# CC2753 register map
File version: 1.0
CPU: CM0+ r0p4, little endian, no MPU, no FPU, VTOR, 3 interrupt priority bits
Registers are 32-bit, read-write, reset 0x0 unless marked. A register's access mark holds for its fields unless they carry their own. Offsets are from the block's base; [hi:lo] are bit positions; {n}, {i} and the like mark numbered series; 'fields as' and 'values as' point back to an identical list.

## SYS0 — This is top module of SYS0
Base 0x40004000
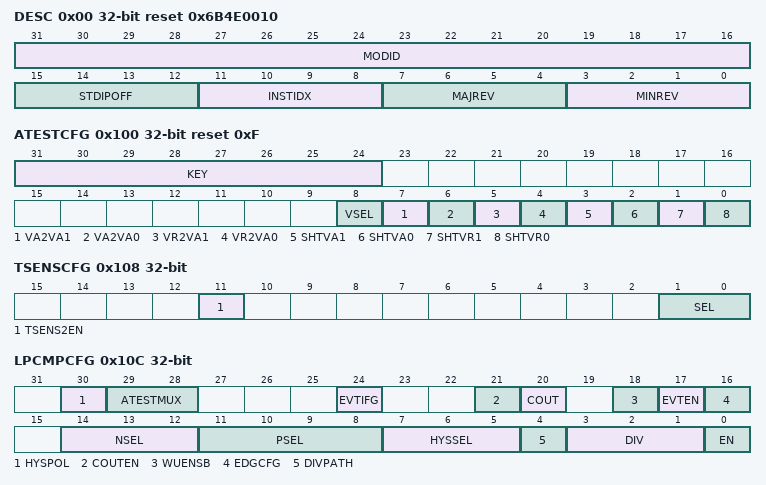
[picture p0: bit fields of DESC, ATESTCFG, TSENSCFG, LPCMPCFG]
0x00 DESC ro reset 0x6B4E0010 — Description Register This register provides IP module ID, revision information, instance index and standard MMR registers offset.
  [31:16] MODID — Module Identifier is used to uniquely identify this IP
  [15:12] STDIPOFF — Standard IP MMR block offset. Standard IP MMRs are the set from aggregated IRQ registers till DTB. 0: Standard IP MMRs do not exist 0x1-0xF: Standard IP MMRs begin at offset of (64*STDIPOFF from the base IP address)
  [11:8] INSTIDX — IP Instance ID number. If multiple instances of IP exist in the device, this field can identify the instance number (0-15).
  [7:4] MAJREV — Major revision of IP (0-15).
  [3:0] MINREV — Minor revision of IP (0-15).
0x0C MUNLOCK wo — Mutable section Unlock This register unlocks registers in mutable section
  [31:0] KEY — Write the unlock key 0xC5AF6927 to temporarily unlock registers in mutable section. The lock is set automatically if no write accesses, to the mutable section, are detected for consecutive 32 CLKULL (24MHz) clock cycles. Writing any value other than that, the unlock key will immediately lock the mutable register space for write access.
    0xC5AF6927=UNLOCK (Unlock registers in the mutable section); 0=LOCK (Lock registers in the mutable section)
0x100 ATESTCFG reset 0xF — ATEST Configuration This register is used to configure analog switches in ATEST module.
  [31:24] KEY wo — Key must be written with value 0x5A for successful write to ATESTCFG and to unlock register state. Write with any value other than 0x5A to KEY will be ignored and register content is not updated. It is recommended to write this register with incorrect KEY to lock back register state after necessary ATESTCFG updates are done. Read value of KEY is 0x0.
  [8] VSEL — Selects supply for ATEST switches.
    1=VDDS (Selects VDDS); 0=VDDBST (Selects VDDBOOST)
  [7] VA2VA1 — Enables isolation switch between VA_ATEST_A1 and VA_PAD_A1.
    1=CLOSE (Switch is closed); 0=OPEN (Switch is open)
  [6] VA2VA0 — Enables isolation switch between VA_ATEST_A0 and VA_PAD_A0.
    1=CLOSE (Switch is closed); 0=OPEN (Switch is open)
  [5] VR2VA1 — Enables isolation switch between VR_ATEST_A1 and VA_ATEST_A1.
    1=CLOSE (Switch is closed); 0=OPEN (Switch is open)
  [4] VR2VA0 — Enables isolation switch between VR_ATEST_A0 and VA_ATEST_A0.
    1=CLOSE (Switch is closed); 0=OPEN (Switch is open)
  [3] SHTVA1 — Shorts VA_ATEST_A1 to ground.
    1=CLOSE (Switch is closed); 0=OPEN (Switch is open)
  [2] SHTVA0 — Shorts VA_ATEST_A0 to ground.
    1=CLOSE (Switch is closed); 0=OPEN (Switch is open)
  [1] SHTVR1 — Shorts VR_ATEST_A1 to ground.
    1=CLOSE (Switch is closed); 0=OPEN (Switch is open)
  [0] SHTVR0 — Shorts VR_ATEST_A0 to ground.
    1=CLOSE (Switch is closed); 0=OPEN (Switch is open)
0x108 TSENSCFG — TSENSE Configuration This register is used to configure temperature sensor module.
  [11] TSENS2EN — This is the enable bit for the second temperature sensor in AUX.
    1=EN (Second temperature sensor is enabled.); 0=DIS (Second temperature sensor is disabled.)
  [1:0] SEL — Used to enable and configure temperature sensor module. Setting the value to 0x3 will disable the temperature sensor.
    2=GND (20uA current is injected on VR_ATEST_A0 and ground measured on VR_ATEST_A1); 1=VALUE (20uA current is injected on VR_ATEST_A0 and voltage measured on VR_ATEST_A1); 0=DISABLE (Temperature sensor is disabled)
0x10C LPCMPCFG — LPCMP configuration This register is used to configure and check the status of low-power comparator (LPCOMP) module.
  [30] HYSPOL — Hysteresis polarity
    1=INV (Inverted); 0=NOINV (Not inverted)
  [29:28] ATESTMUX — Used to configure ATEST mux in comparator module and provides chosen output on VA_ATEST_A0. Note: This bit field is write-protected using global lock indicator on production device.
    3=IBIASOUT (Selects bias current output); 2=COMP_VIN_NEG (Selects voltage divider output); 1=COMPOUT (Selects comparator output); 0=OFF (ATEST mux is off)
  [24] EVTIFG — Event flag The event flag is set when the comparator output transition is qualified based on the edge polarity configuration in EDGCFG.
    1=SET; 0=CLR (Clear)
  [21] COUTEN — Enables LPCOMP output on device pin.
    1=EN (Enabled); 0=DIS (Disabled)
  [20] COUT ro — LPCOMP output status. This bit captures the value LPCOMP raw output.
    1=HIGH (Output is high); 0=LOW (Output is low)
  [18] WUENSB — Enables lpcmpcfg output to wake device from standby.
    1=EN (Enable); 0=DIS (Disable)
  [17] EVTEN — Enables event generation. Comparator module will produce event on ULL event fabric when EVTIFG is set.
    1=EN (Enable); 0=DIS (Disable)
  [16] EDGCFG — Selects positive edge or negative edge detection on comparator output to set the event flag
    1=FALL (Fall edge detection); 0=RISE (Rise edge detection)
  [14:12] NSEL — Negative input selection. Setting values 0x5-0x7 will open all the switches.
    4=VDDD (Selects VDDD); 3=VDDS (Selects VDDS); 2=VA_PAD_A3 (Selects VA_PAD_A3); 1=VA_PAD_A2 (Selects VA_PAD_A2); 0=OPEN (All switches are open)
  [11:8] PSEL — Positive input selection. Setting values 0x9-0xF will open all the switches.
    8=VDDS (Selects VDDS); 7=VA_ATEST_A1 (Selects VA_ATEST_A1); 6=VA_ATEST_A0 (Selects VA_ATEST_A0); 5=VR_ATEST_A1 (Selects VR_ATEST_A1); 4=VR_ATEST_A0 (Selects VR_ATEST_A0); 3=VA_PAD_A3 (Selects VA_PAD_A3); 2=VA_PAD_A2 (Selects VA_PAD_A2); 1=VA_PAD_A1 (Selects VA_PAD_A1); 0=OPEN (All switches are open)
  [7:5] HYSSEL — Used to enable and select hysteresis level Hysteresis is disabled when HYSSEL = 0 and enabled for other values of HYSSEL from 1 to 7. Refer to device specific datasheet for individual hysteresis values.
    {v}=Hysteresis value {v} (v=1..7); 0=Hysteresis is disabled
  [4] DIVPATH — Used to select the path on which voltage divider is applied
    1=PSIDE (Divider is applied on P-side); 0=NSIDE (Divider is applied on N-side)
  [3:1] DIV — Used to configure reference divider. Setting values 0x5-0x7 will set the divide value to 1.
    4=Divide value is 1/4; 3=Divide value is 1/3; 2=Divide value is 1/2; 1=Divide value is 3/4; 0=Divide value is 1
  [0] EN — Used to enable comparator module.
    1=EN (Enable); 0=DIS (Disable)
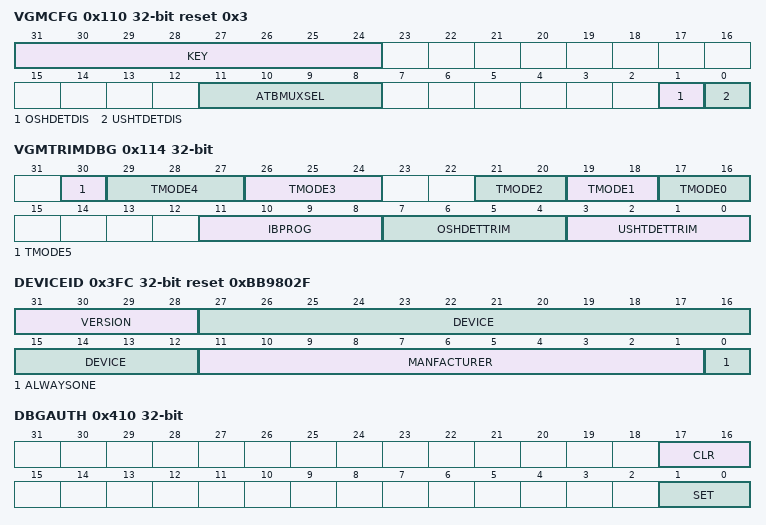
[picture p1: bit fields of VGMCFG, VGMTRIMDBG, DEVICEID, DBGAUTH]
0x110 VGMCFG reset 0x3 — This register is used to configure the VGM module.
  [31:24] KEY wo — Key must be written with value 0x5A for successful write to VGMCFG and to unlock register state. Write with any value other than 0x5A to KEY will be ignored and the register content is not updated. Read value of KEY is 0x0.
  [11:8] ATBMUXSEL — These bits are used to generate VGM ATB mux selection control.
  [1] OSHDETDIS — Disables overshoot detector in VGM.
    1=DIS (Disable); 0=EN (Enable)
  [0] USHTDETDIS — Disables undershoot detector in VGM.
    1=DIS (Disable); 0=EN (Enable)
0x114 VGMTRIMDBG — This register is used to trim and debug VGM module.
  [30] TMODE5 — Test mode bit for glitchy supply mux selection.
  [29:27] TMODE4 — Test mode bits for VREF mux selection for overshoot detector.
  [26:24] TMODE3 — Test mode bits for VREF mux selection for undershoot detector.
  [21:20] TMODE2 — Test mode for level shifter isolation.
  [19:18] TMODE1 — Test mode bits for low voltage SR latch reset.
  [17:16] TMODE0 — Test mode bits for 3V SR latch reset.
  [11:8] IBPROG — These bits are used to program VGM bias current generator.
  [7:4] OSHDETTRIM — These bits are used to trim VGM overshoot detector.
  [3:0] USHTDETTRIM — These bits are used to trim VGM undershoot detector.
0x3FC DEVICEID ro reset 0xBB9802F — Device ID This register provides Device ID information. Note: This 32-bit register value is provided as output to DEBUGSS.
  [31:28] VERSION — Monotonic increasing value indicating new hardware revision. A newer hardware revision shall never have a lower version than an older revision of hardware.
  [27:12] DEVICE — Value generated by RAMP for the SOC. This value uniquely identifies the die from any other TI device.
  [11:1] MANFACTURER — JEP 106 assigned manufacturer ID. This field identifies the device as a Texas Instruments device.
  [0] ALWAYSONE — Value 1 in this bit field means that a 32-bit scan register exists.
0x410 DBGAUTH wo — Debug Authentication. This register is used by ROM to store Debug Authnetication Status
  [17:16] CLR — Clears Authentication Status
  [1:0] SET — Sets Authentication Status
    3=SEC (Secure Debug Authorized); 2=NONSEC (Non-Secure Debug Authorized); 1=NONINV (Only Non-Invasive Debug Authorized); 0=UNAUTH (Debug Unauthorized)
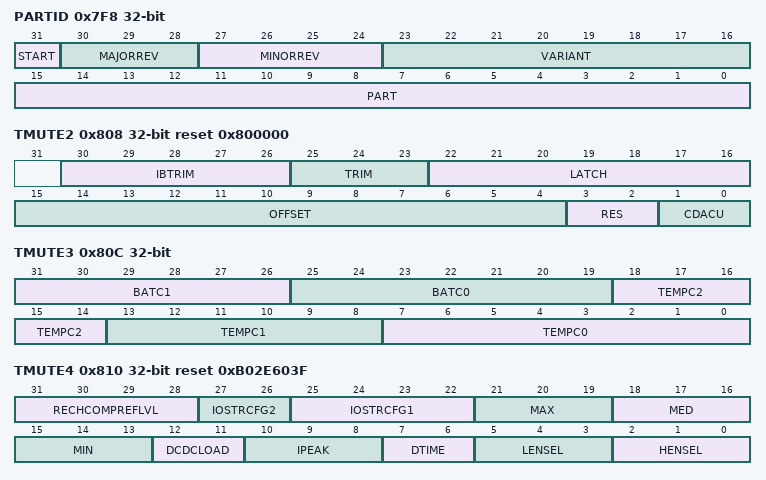
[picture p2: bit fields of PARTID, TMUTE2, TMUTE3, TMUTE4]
0x7F8 PARTID — Part ID This register is programmed by boot code with Part ID information. Note: This 32-bit register value is provided as output to DEBUGSS
  [31] START — Start bit
    1=SET; 0=CLR (Clear)
  [30:28] MAJORREV — Monotonic increasing value indicating a new revision of the SKU significant enough that users of the device may have to revise PCB or software design
  [27:24] MINORREV — Monotonic increasing value indicating a new revision of the SKU that preserves compatibility with lesser MINORREV values
  [23:16] VARIANT — Bit pattern uniquely identifying a variant of a part
  [15:0] PART — Bit pattern uniquely identifying a part
0x7FC LIFECYC — This register is programmed by boot code with device life cycle information
  [7:0] VAL — Device life cycle value.
    255=LCYCLE_ILLEGAL (Illegal); 6=LCYCLE_RETEST (Re-test); 5=LCYCLE_PRODDEV (Production device); 4=LCYCLE_ENGRDEV (Engineering device); 3=LCYCLE_TESTFT (Test Final Test); 2=LCYCLE_TESTPT (Test Production Test); 1=LCYCLE_1STBDAY (First birthday); 0=LCYCLE_POSSIBLE_1STBDAY (Possible first birthday)
0x800 TMUTE0 — Internal. Only to be used through TI provided API.
  [31:0] CDACL
0x804 TMUTE1 — Internal. Only to be used through TI provided API.
  [31:0] CDACM
0x808 TMUTE2 reset 0x800000 — TMUTE2 trim Register
  [30:26] IBTRIM — LPCOMP: Bias current trim, 250nA to be terminated across I2V, 1M ohm setting. Resulting target trim voltage 250mV.
  [25:23] TRIM — ADC REFBUF trim bits.
  [22:16] LATCH — SOC ADC: Latch trim bits. These bits are used in the analog IP.
  [15:4] OFFSET — SOCADC: Offset trim bits. These bits are used in DTC.
  [3:2] RES — SOCADC: Resistor trim bits. These bits are used in the analog IP.
  [1:0] CDACU — SOCADC: Upper 2 bits of CDAC trim. These bits are used in DTC.
0x80C TMUTE3 — Internal. Only to be used through TI provided API.
  [31:26] BATC1 — Internal. Only to be used through TI provided API.
  [25:19] BATC0 — Internal. Only to be used through TI provided API.
  [18:14] TEMPC2 — Internal. Only to be used through TI provided API.
  [13:8] TEMPC1 — Internal. Only to be used through TI provided API.
  [7:0] TEMPC0 — Internal. Only to be used through TI provided API.
0x810 TMUTE4 reset 0xB02E603F — TMUTE4 trim Register
  [31:28] RECHCOMPREFLVL — Internal. Only to be used through TI provided API.
  [27:26] IOSTRCFG2 — Internal. Only to be used through TI provided API.
  [25:22] IOSTRCFG1 — Internal. Only to be used through TI provided API.
  [21:19] MAX — Internal. Only to be used through TI provided API.
  [18:16] MED — Internal. Only to be used through TI provided API.
  [15:13] MIN — Internal. Only to be used through TI provided API.
  [12:11] DCDCLOAD — Internal. Only to be used through TI provided API.
  [10:8] IPEAK — Internal. Only to be used through TI provided API.
  [7:6] DTIME — Internal. Only to be used through TI provided API.
  [5:3] LENSEL — Internal. Only to be used through TI provided API.
  [2:0] HENSEL — Internal. Only to be used through TI provided API.
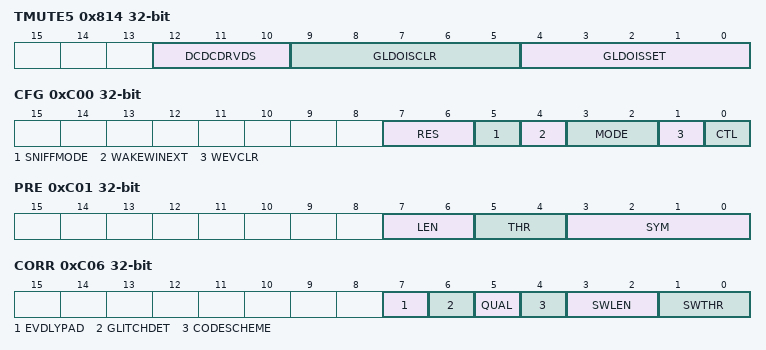
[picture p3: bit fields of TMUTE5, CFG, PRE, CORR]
0x814 TMUTE5 — Internal. Only to be used through TI provided API.
  [12:10] DCDCDRVDS — Internal. Only to be used through TI provided API.
  [9:5] GLDOISCLR wo — Internal. Only to be used through TI provided API.
  [4:0] GLDOISSET wo — Internal. Only to be used through TI provided API.
0xC00 CFG — Config Register contains general configuration: - Timer resolution - Sniff mode enable - Wake window extension enable - Mode of operation - Wake-up flag clearing - Module enable
  [7:6] RES — Timer Resolution This field shall only be written to when [SYS0.CFG.CTL] == DIS. Field determines the resolution of the timer values in registers SYS0.TIM0 SYS0.TIM1 SYS0.TIM2. 1 LSB in the timer values = (4 $lt;$lt; [SYS0.CFG.RES]) ms.
    3=_32Ms (One LSB in the timer values = 32 ms); 2=_16MS (One LSB in the timer values = 16 ms); 1=_8MS (One LSB in the timer values = 8 ms); 0=_4MS (One LSB in the timer values = 4 ms)
  [5] SNIFFMODE — Sniff Mode Enable This field shall only be written to when [SYS0.CFG.CTL] == DIS. Field enables sniff mode, where WuRX will duty cycle on and off while active until incoming energy is detected. When [SYS0.CFG.MODE] == WAKE0, sniff mode requires [SYS0.PRE.LEN] to be 8BIT or 16BIT.
    1=EN (Sniff mode enabled); 0=DIS (Sniff mode disabled)
  [4] WAKEWINEXT — Wake Window Extension This field shall only be written to when [SYS0.CFG.CTL] == DIS. Field determines if wake window should be extended when preamble is detected and remaining active time is too short for sync word detection. When [SYS0.CFG.SNIFFMODE] == DIS, wake window extension requires [SYS0.PRE.LEN] to be nonzero.
    1=EN (Wake window extension enabled); 0=DIS (Wake window extension disabled)
  [3:2] MODE — Mode of Operation This field shall only be written to when [SYS0.CFG.CTL] == DIS. Field determines the mode of operation.
    3=ATEST (Analog test mode); 2=TIMER (Timer mode); 1=WAKE1 (Wake mode1, where patterns are sent back to back); 0=WAKE0 (Wake mode 0, where there are silent intervals between patterns)
  [1] WEVCLR — Wakeup Event Clear This field may be written to at any time. Field determines if the output event flags are enabled or disabled. When enabled, events can be generated, and any event flag set high will be kept high indefinitely. When disabled, events will not be generated, and any event flags already set high will be set low. While [SYS0.CFG.CTL] == DIS, [SYS0.CFG.WEVCLR] will be overridden as if it is set to its disabled state.
    1=EN (Events enabled and kept indefinitely); 0=DIS (Events disabled and cleared)
  [0] CTL — Control This field may be written to at any time. Field determines if the controller is enabled or disabled. Field shall be 0 when the module is being configured and must only be set to 1 to enable functional operation.
    1=EN (Module is enabled); 0=DIS (Module is disabled)
0xC01 PRE — Preamble Register contains preamble configuration: - Length - Threshold - Symbols
  [7:6] LEN — Preamble Length This field shall only be written to when [SYS0.CFG.CTL] == DIS. Field determines the preamble length. Preamble length must be nonzero when [SYS0.CFG.SNIFFMODE] == DIS $amp;$amp; [SYS0.CFG.WAKEWINEXT] == EN. Preamble length must be 8BIT or 16BIT when [SYS0.CFG.SNIFFMODE] == EN $amp;$amp; [SYS0.CFG.MODE] == WAKE0.
    3=_16BIT (Preamble length = 16 bits); 2=_8BIT (Preamble length = 8 bits); 1=_4BIT (Preamble length = 4 bits); 0=_0BIT (Preamble length = 0 bits)
  [5:4] THR — Preamble Correlation Threshold This field shall only be written to when [SYS0.CFG.CTL] == DIS. Field determines the threshold value used by wake receiver to indicate a preamble correlation event, and is only used if [SYS0.CFG.WAKEWINEXT] = EN. Correlation trigger = Number of non-correlating bits ≤ [SYS0.PRE.THR].
    3=_3BIT (Preamble correlation when up to 3 symbols do not match.); 2=_2BIT (Preamble correlation when up to 2 symbols do not match.); 1=_1BIT (Preamble correlation when up to 1 symbol does not match.); 0=_0BIT (Preamble correlation when all symbols match.)
  [3:0] SYM — Preamble Symbols This field shall only be written to when [SYS0.CFG.CTL] == DIS. Field determines baseband symbols in preamble. Wake receiver expects a preamble equal to this 4-bit pattern repeated [SYS0.PRE.LEN]/4 times, with the MSB transmitted first.
0xC02 SWB0 — Sync Word Byte 0 Register contains sync word byte 0, and is the LSB (least significant byte) of the syncword. Correlator assumes MSB of sync word is transmitted first.
  [7:0] SYM — Sync Word Symbols 7:0 This field shall only be written to when [SYS0.CFG.CTL] == DIS. Field determines baseband symbols 7:0 in sync word. Necessary for all [SYS0.CORR.SWLEN] options.
0xC03 SWB1 — Sync Word Byte 1 Register contains sync word byte 1.
  [7:0] SYM — Sync Word Symbols 15:8 This field shall only be written to when [SYS0.CFG.CTL] == DIS. Field determines baseband symbols 15:8 in sync word. Necessary when [SYS0.CORR.SWLEN] == 1BYTE/2BYTE/3BYTE.
0xC04 SWB2 — Sync Word Byte 2 Register contains sync word byte 2.
  [7:0] SYM — Sync Word Symbols 23:16 This field shall only be written to when [SYS0.CFG.CTL] == DIS. Field determines baseband symbols 23:16 in sync word. Necessary when [SYS0.CORR.SWLEN] == 2BYTE/3BYTE.
0xC05 SWB3 — Sync Word Byte 3 Register contains sync word byte 3.
  [7:0] SYM — Sync Word Symbols 31:24 This field shall only be written to when [SYS0.CFG.CTL] == DIS. Field determines baseband symbols 31:24 in sync word. Necessary when [SYS0.CORR.SWLEN] == 3BYTE.
0xC06 CORR — Correlator Register contains configuration for: - Event delay padding - Glitch detection enable - Correlator qualification - Manchester code scheme - Sync word length - Sync word threshold
  [7] EVDLYPAD — Event Delay Padding This field shall only be written to when [SYS0.CFG.CTL] == DIS. If set, delay between event generation and event signalling when [SYS0.CFG.MODE] == WAKE1 is padded by an extra 12.5%. The nominal delay is one active period, as set by [SYS0.TIM0.ONLSB] and [SYS0.TIM1.ONMSB].
    1=EN (Event delay padding enabled); 0=DIS (Event delay padding disabled)
  [6] GLITCHDET — Glitch Detect Enable This field shall only be written to when [SYS0.CFG.CTL] == DIS. Field enables glitch detection and correction ahead of the decoder. If enabled, a sampled value that is different from both the sample before it and after it will be corrected to be equal to these, i.e. three consecutive samples of 010 or 101 will be corrected to 000 or 111, respectively.
    1=EN (Glitch detection enabled); 0=DIS (Glitch detection disabled)
  [5] QUAL — Correlation Qualification This field shall only be written to when [SYS0.CFG.CTL] == DIS. If set, field ensures no correlation can be signalled until a number of samples equal to the programmed sync word length [SYS0.CORR.SWLEN] have been processed.
    1=EN (Correlation qualification enabled); 0=DIS (Correlation qualification disabled)
  [4] CODESCHEME — Manchester Code Scheme This field shall only be written to when [SYS0.CFG.CTL] == DIS. Field determines the On-Off Keying (OOK) Manchester Coding Scheme. Same scheme is used for preamble and sync word.
    1=IEEE (Bit value 0 corresponds to high level followed by low level, opposite for bit value 1); 0=GETHOMAS (Bit value 0 corresponds to low level followed by high level, opposite for bit value 1)
  [3:2] SWLEN — Sync Word Length This field shall only be written to when [SYS0.CFG.CTL] == DIS. For sync word of length N bytes, the lower N bytes of registers SYS0.SWB0 SYS0.SWB1 SYS0.SWB2 SYS0.SWB3 are used.
    3=_4BYTE (Sync word length = 4 bytes); 2=_3BYTE (Sync word length = 3 bytes); 1=_2BYTE (Sync word length = 2 bytes); 0=_1BYTE (Sync word length = 1 byte)
  [1:0] SWTHR — Sync Word Correlation Threshold This field shall only be written to when [SYS0.CFG.CTL] == DIS. Field determines the threshold value used by wake receiver to indicate a sync word correlation event. Correlation trigger = Number of non-correlating bits ≤ [SYS0.CORR.SWTHR].
    3=_3BIT (Sync word correlation when up to 3 symbols do not match.); 2=_2BIT (Sync word correlation when up to 2 symbols do not match.); 1=_1BIT (Sync word correlation when up to 1 symbol does not match.); 0=_0BIT (Sync word correlation when all symbols match.)
0xC07 TIM0 — Time 0 Register contains 8 LSBs of the on-time.
  [7:0] ONLSB — On-time Value Bits 7:0 This field shall only be written to when [SYS0.CFG.CTL] == DIS. On-time value = ([SYS0.TIM1.ONMSB] $lt;$lt; 8) + [SYS0.TIM0.ONLSB], in units of (4 $lt;$lt; [SYS0.CFG.RES]) ms. When [SYS0.CFG.MODE] == WAKE0, this is the active duration of the receiver, where it searches for a transmission. When [SYS0.CFG.MODE] == WAKE1, this is the active duration of the receiver, where it searches for a transmission. It is also the delay between an incoming sync word being detected and the output event flag being set high, optionally padded by an extra 12.5% if [SYS0.CORR.EVDLYPAD] == EN. When [SYS0.CFG.MODE] == TIMER/ATEST, this is unused.
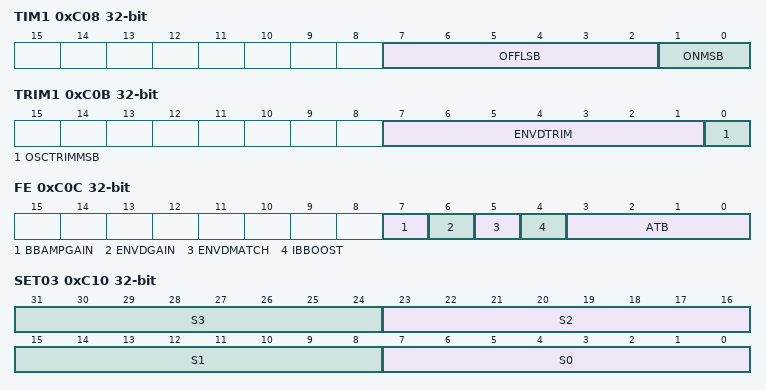
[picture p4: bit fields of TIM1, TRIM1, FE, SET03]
0xC08 TIM1 — Time 1 Register contains 2 MSBs of the on-time and 6 LSBs of the off-time.
  [7:2] OFFLSB — Off-time Value Bits 5:0 This field shall only be written to when [SYS0.CFG.CTL] == DIS. Off-time value = ([SYS0.TIM2.OFFMSB] $lt;$lt; 6) + [SYS0.TIM1.OFFLSB], in units of (4 $lt;$lt; [SYS0.CFG.RES]) ms. When [SYS0.CFG.MODE] == WAKE0/WAKE1, this is the inactive duration of the receiver. When [SYS0.CFG.MODE] == TIMER, this is the period of the wake-up events. When [SYS0.CFG.MODE] == ATEST, this is unused.
  [1:0] ONMSB — On-time Value Bits 9:8 This field shall only be written to when [SYS0.CFG.CTL] == DIS. On-time value = (SYS0.ONMSB $lt;$lt; 8) + [SYS0.TIM0.ONLSB], in units of (4 $lt;$lt; [SYS0.CFG.RES]) ms. When [SYS0.CFG.MODE] == WAKE0, this is the active duration of the receiver, where it searches for a transmission. When [SYS0.CFG.MODE] == WAKE1, this is the active duration of the receiver, where it searches for a transmission. It is also the delay between an incoming sync word being detected and the output event flag being set high, optionally padded by an extra 12.5% if [SYS0.CORR.EVDLYPAD] == EN. When [SYS0.CFG.MODE] == TIMER/ATEST, this is unused.
0xC09 TIM2 — Time 2 Register contains 8 MSBs of the off-time.
  [7:0] OFFMSB — Off-time Value Bits 13:6 This field shall only be written to when [SYS0.CFG.CTL] == DIS. Off-time value = ([SYS0.TIM2.OFFMSB] $lt;$lt; 6) + [SYS0.TIM1.OFFLSB], in units of (4 $lt;$lt; [SYS0.CFG.RES]) ms. When [SYS0.CFG.MODE] == WAKE0/WAKE1, this is the inactive duration of the receiver. When [SYS0.CFG.MODE] == TIMER, this is the period of the wake-up events. When [SYS0.CFG.MODE] == ATEST, this is unused.
0xC0A TRIM0 — Trim 0 Register contains the 8 MSBs of the ULFOSC trim.
  [7:0] OSCTRIMLSB — Oscillator Trim MSB This field shall only be written to when [SYS0.CFG.CTL] == DIS. The trim value is located in FCFG. The oscillator trim = ([SYS0.TRIM1.OSCTRIMMSB] $lt;$lt; 8) + [SYS0.TRIM0.OSCTRIMLSB]. The trim is unsigned and software must flip the MSB to create the final value. With the MSB flipped, this results in: - Lowest frequency corresponds to logical trim value 0 and field value 9'd256. - Highest frequency corresponds to logical trim value 511 and field value 9'd255."
0xC0B TRIM1 — Trim 1 Register contains the envelope detector trim and the MSB of the ULFOSC trim.
  [7:1] ENVDTRIM — Envelope Detector Trim This field shall only be written to when [SYS0.CFG.CTL] == DIS. The trim value is located in FCFG. Field configures envelope detector trim.
  [0] OSCTRIMMSB — Oscillator Trim MSB This field shall only be written to when [SYS0.CFG.CTL] == DIS. The trim value is located in FCFG. The oscillator trim = ([SYS0.TRIM1.OSCTRIMMSB] $lt;$lt; 8) + [SYS0.TRIM0.OSCTRIMLSB]. The trim is unsigned and software must flip the MSB to create the final value. With the MSB flipped, this results in: - Lowest frequency corresponds to logical trim value 0 and field value 9'd256. - Highest frequency corresponds to logical trim value 511 and field value 9'd255.
0xC0C FE — Frontend Configuration Register contains analog frontend configuration: - Baseband amplifier gain enable - Envelope detector gain enable - Envelope detector match enable - Ibias current boost enable - Analog test bus control
  [7] BBAMPGAIN — Baseband Amplifier Gain This field shall only be written to when [SYS0.CFG.CTL] == DIS. Field configures analog gain control found in characterization for the baseband amplifier. The gain control enable/disable value is the same for all devices, and must be set to this value.
    1=EN (Baseband amplifier gain enabled); 0=DIS (Baseband amplifier gain disabled)
  [6] ENVDGAIN — Envelope Detector Gain This field shall only be written to when [SYS0.CFG.CTL] == DIS. Field configures analog gain control for the envelope detector.
    1=EN (Envelope detector gain enabled); 0=DIS (Envelope detector gain disabled)
  [5] ENVDMATCH — Envelope Detector Match Enable This field shall only be written to when [SYS0.CFG.CTL] == DIS. Field configures analog envelope detector matching found in characterization. The envelope detector match enable/disable value is the same for all devices, and must be set to this value.
    1=EN (Envelope detector match enabled); 0=DIS (Envelope detector match disabled)
  [4] IBBOOST — Ibias Current Boost Enable This field shall only be written to when [SYS0.CFG.CTL] == DIS. Field configures Ibias current boost. The Ibias current boost enable/disable value is located in FCFG.
    1=EN (Ibias boost enabled); 0=DIS (Ibias boost disabled)
  [3:0] ATB — Analog Test Bus This field shall only be written to when [SYS0.CFG.CTL] == DIS. Field determines which analog node connects to the Analog Test Bus (ATB). SW must always ensure one-hot value, and always perform break-before-make (0-value) between different one-hot values.
    8=ULFOSC (ATB connected to ULFOSC); 4=CMPOUT (ATB connected to comparator output); 2=BBOUTN (ATB connected to baseband amplifier negative output); 1=BBOUTP (ATB connected to baseband amplifier positive output); 0=NC (ATB not connected)
0xC0D ANASPARE — Analog spare register Register is a planned spare byte for future analog needs.
  [7:0] SPARE — Spare This field shall only be written to when [SYS0.CFG.CTL] == DIS.
0xC0E SPARE — Spare register Register is a spare byte, with no current or planned purpose.
  fields as ANASPARE
0xC0F READONLY ro — Read-only register Register is read-only, with no current or planned purpose.
  [7:0] READONLY — Read-only This field is read-only.
0xC10 SET03 — Set for ADI Byte Offsets 0 to 3
  [8n+7:8n] S{n} (n=0..3) — A high bit value will set the corresponding bit in ADI register {n}. Read returns 0.
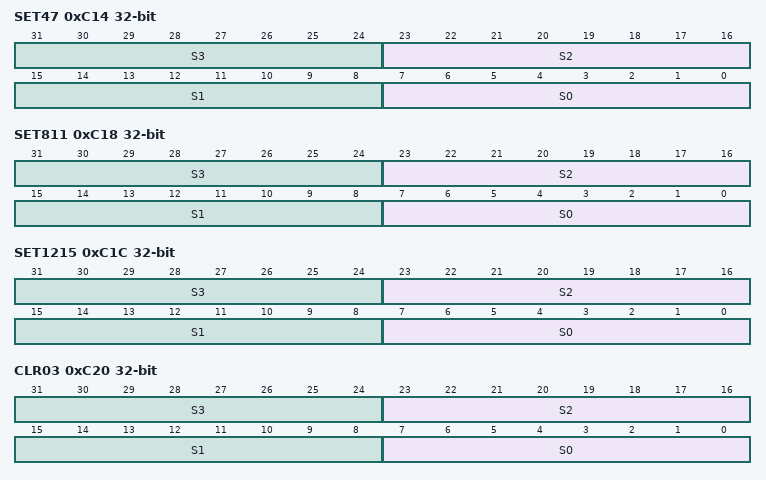
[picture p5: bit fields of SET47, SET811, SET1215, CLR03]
0xC14 SET47 — Set for ADI Byte Offsets 4 to 7
  [8n+7:8n] S{n} (n=0..3) — A high bit value will set the corresponding bit in ADI register {n+4}. Read returns 0.
0xC18 SET811 — Set for ADI Byte Offsets 8 to 11
  [8n+7:8n] S{n} (n=0..3) — A high bit value will set the corresponding bit in ADI register {n+8}. Read returns 0.
0xC1C SET1215 — Set for ADI Byte Offsets 12 to 15
  [8n+7:8n] S{n} (n=0..3) — A high bit value will set the corresponding bit in ADI register {n+12}. Read returns 0.
0xC20 CLR03 — Clear for ADI Byte Offsets 0 to 3
  [8n+7:8n] S{n} (n=0..3) — A high bit value will clear the corresponding bit in ADI register {n}. Read returns 0.
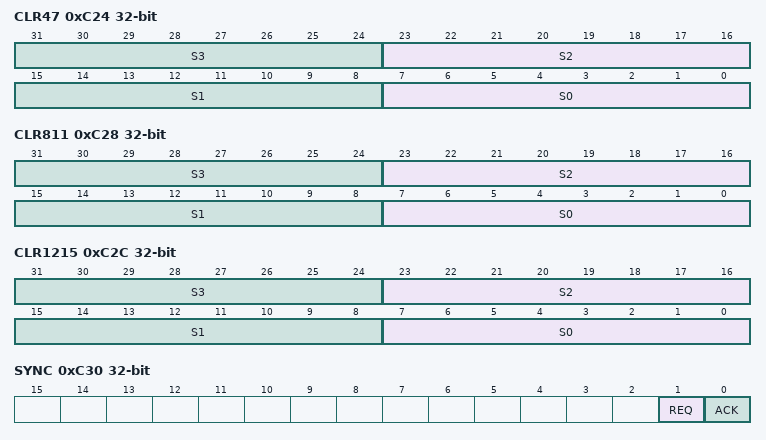
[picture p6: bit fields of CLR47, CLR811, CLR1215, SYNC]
0xC24 CLR47 — Clear for ADI Byte Offsets 4 to 7
  [8n+7:8n] S{n} (n=0..3) — A high bit value will clear the corresponding bit in ADI register {n+4}. Read returns 0.
0xC28 CLR811 — Clear for ADI Byte Offsets 8 to 11
  [8n+7:8n] S{n} (n=0..3) — A high bit value will clear the corresponding bit in ADI register {n+8}. Read returns 0.
0xC2C CLR1215 — Clear for ADI Byte Offsets 12 to 15
  [8n+7:8n] S{n} (n=0..3) — A high bit value will clear the corresponding bit in ADI register {n+12}. Read returns 0.
0xC30 SYNC — Synchronization
  [1] REQ — Read current value of DI_REQ signal. Writing 0 to this bit forces a sync with slave, ensuring that req will be 0. It is recommended to write 0 to this register before power down of the master.
  [0] ACK ro — Read current value of DI_ACK signal
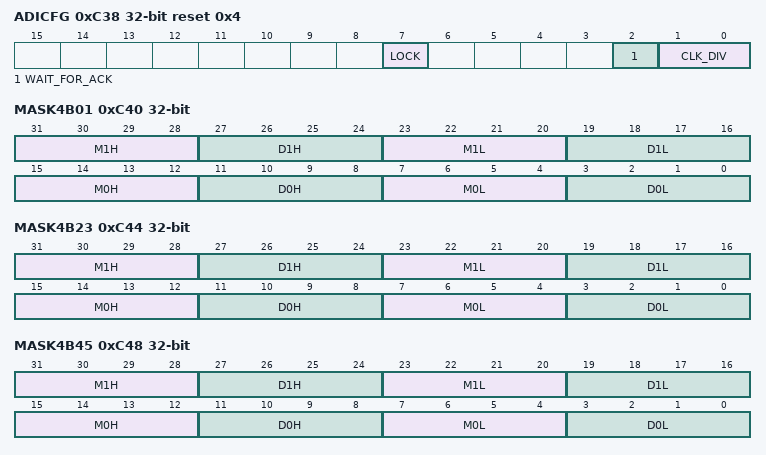
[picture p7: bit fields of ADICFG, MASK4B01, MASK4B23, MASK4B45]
0xC38 ADICFG reset 0x4 — ADI Configuration
  [7] LOCK — This register is no longer accessible when this bit is set (unless sticky_bit_overwrite is asserted on top module).
  [2] WAIT_FOR_ACK — A transaction on the ADI interface does not end until ack has been received from the slave when this bit is set.
  [1:0] CLK_DIV — Sets the period of ADI transactions. ADI clock rising edge occurs in the middle of the period. Data and control to slave is set up in the beginning of the cycle, and data from slave is read after the transaction.
    3=DIV16 (One ADI transaction takes 16 master clock cycles); 2=DIV8 (One ADI transaction takes 8 master clock cycles); 1=DIV4 (One ADI transaction takes 4 master clock cycles); 0=DIV2 (One ADI transaction takes 2 master clock cycles)
0xC40 MASK4B01 wo — Masked Access (4m/4d), Byte Offsets 0 and 1.
  [31:28] M1H — Mask for bits [7:4] in ADI register 1
  [27:24] D1H — Data for bits [7:4] in ADI register 1, only bits selected by mask M1H will be affected by access
  [23:20] M1L — Mask for bits [3:0] in ADI register 1
  [19:16] D1L — Data for bits [3:0] in ADI register 1, only bits selected by mask M1L will be affected by access
  [15:12] M0H — Mask for bits [7:4] in ADI register 0
  [11:8] D0H — Data for bits [7:4] in ADI register 0, only bits selected by mask M0H will be affected by access
  [7:4] M0L — Mask for bits [3:0] in ADI register 0
  [3:0] D0L — Data for bits [3:0] in ADI register 0, only bits selected by mask M0L will be affected by access
0xC44 MASK4B23 wo — Masked Access (4m/4d), Byte Offsets 2 and 3.
  [31:28] M1H — Mask for bits [7:4] in ADI register 3
  [27:24] D1H — Data for bits [7:4] in ADI register 3, only bits selected by mask M1H will be affected by access
  [23:20] M1L — Mask for bits [3:0] in ADI register 3
  [19:16] D1L — Data for bits [3:0] in ADI register 3, only bits selected by mask M1L will be affected by access
  [15:12] M0H — Mask for bits [7:4] in ADI register 2
  [11:8] D0H — Data for bits [7:4] in ADI register 2, only bits selected by mask M0H will be affected by access
  [7:4] M0L — Mask for bits [3:0] in ADI register 2
  [3:0] D0L — Data for bits [3:0] in ADI register 2, only bits selected by mask M0L will be affected by access
0xC48 MASK4B45 wo — Masked Access (4m/4d), Byte Offsets 4 and 5.
  [31:28] M1H — Mask for bits [7:4] in ADI register 5
  [27:24] D1H — Data for bits [7:4] in ADI register 5, only bits selected by mask M1H will be affected by access
  [23:20] M1L — Mask for bits [3:0] in ADI register 5
  [19:16] D1L — Data for bits [3:0] in ADI register 5, only bits selected by mask M1L will be affected by access
  [15:12] M0H — Mask for bits [7:4] in ADI register 4
  [11:8] D0H — Data for bits [7:4] in ADI register 4, only bits selected by mask M0H will be affected by access
  [7:4] M0L — Mask for bits [3:0] in ADI register 4
  [3:0] D0L — Data for bits [3:0] in ADI register 4, only bits selected by mask M0L will be affected by access
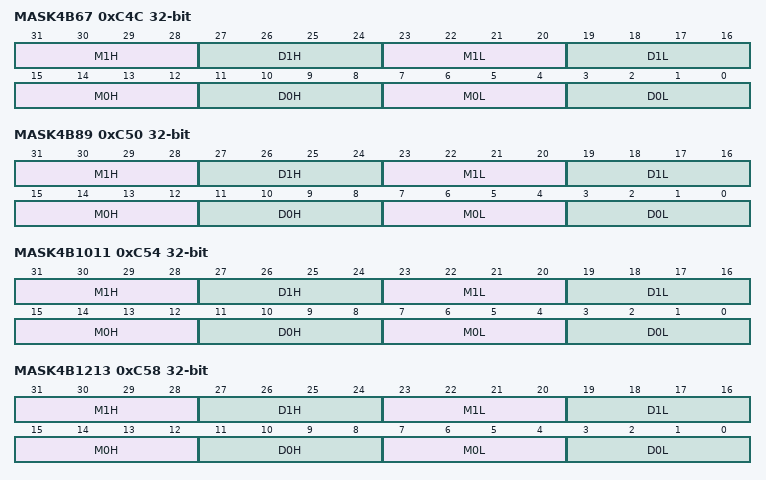
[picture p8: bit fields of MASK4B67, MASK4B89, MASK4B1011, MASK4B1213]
0xC4C MASK4B67 wo — Masked Access (4m/4d), Byte Offsets 6 and 7.
  [31:28] M1H — Mask for bits [7:4] in ADI register 7
  [27:24] D1H — Data for bits [7:4] in ADI register 7, only bits selected by mask M1H will be affected by access
  [23:20] M1L — Mask for bits [3:0] in ADI register 7
  [19:16] D1L — Data for bits [3:0] in ADI register 7, only bits selected by mask M1L will be affected by access
  [15:12] M0H — Mask for bits [7:4] in ADI register 6
  [11:8] D0H — Data for bits [7:4] in ADI register 6, only bits selected by mask M0H will be affected by access
  [7:4] M0L — Mask for bits [3:0] in ADI register 6
  [3:0] D0L — Data for bits [3:0] in ADI register 6, only bits selected by mask M0L will be affected by access
0xC50 MASK4B89 wo — Masked Access (4m/4d), Byte Offsets 8 and 9.
  [31:28] M1H — Mask for bits [7:4] in ADI register 9
  [27:24] D1H — Data for bits [7:4] in ADI register 9, only bits selected by mask M1H will be affected by access
  [23:20] M1L — Mask for bits [3:0] in ADI register 9
  [19:16] D1L — Data for bits [3:0] in ADI register 9, only bits selected by mask M1L will be affected by access
  [15:12] M0H — Mask for bits [7:4] in ADI register 8
  [11:8] D0H — Data for bits [7:4] in ADI register 8, only bits selected by mask M0H will be affected by access
  [7:4] M0L — Mask for bits [3:0] in ADI register 8
  [3:0] D0L — Data for bits [3:0] in ADI register 8, only bits selected by mask M0L will be affected by access
0xC54 MASK4B1011 wo — Masked Access (4m/4d), Byte Offsets 10 and 11.
  [31:28] M1H — Mask for bits [7:4] in ADI register 11
  [27:24] D1H — Data for bits [7:4] in ADI register 11, only bits selected by mask M1H will be affected by access
  [23:20] M1L — Mask for bits [3:0] in ADI register 11
  [19:16] D1L — Data for bits [3:0] in ADI register 11, only bits selected by mask M1L will be affected by access
  [15:12] M0H — Mask for bits [7:4] in ADI register 10
  [11:8] D0H — Data for bits [7:4] in ADI register 10, only bits selected by mask M0H will be affected by access
  [7:4] M0L — Mask for bits [3:0] in ADI register 10
  [3:0] D0L — Data for bits [3:0] in ADI register 10, only bits selected by mask M0L will be affected by access
0xC58 MASK4B1213 wo — Masked Access (4m/4d), Byte Offsets 12 and 13.
  [31:28] M1H — Mask for bits [7:4] in ADI register 13
  [27:24] D1H — Data for bits [7:4] in ADI register 13, only bits selected by mask M1H will be affected by access
  [23:20] M1L — Mask for bits [3:0] in ADI register 13
  [19:16] D1L — Data for bits [3:0] in ADI register 13, only bits selected by mask M1L will be affected by access
  [15:12] M0H — Mask for bits [7:4] in ADI register 12
  [11:8] D0H — Data for bits [7:4] in ADI register 12, only bits selected by mask M0H will be affected by access
  [7:4] M0L — Mask for bits [3:0] in ADI register 12
  [3:0] D0L — Data for bits [3:0] in ADI register 12, only bits selected by mask M0L will be affected by access
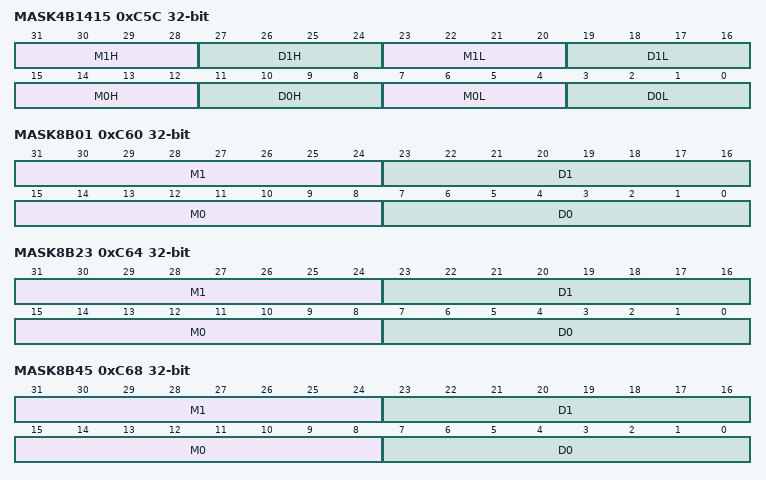
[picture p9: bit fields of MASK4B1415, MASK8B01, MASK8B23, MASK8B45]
0xC5C MASK4B1415 wo — Masked Access (4m/4d), Byte Offsets 14 and 15.
  [31:28] M1H — Mask for bits [7:4] in ADI register 15
  [27:24] D1H — Data for bits [7:4] in ADI register 15, only bits selected by mask M1H will be affected by access
  [23:20] M1L — Mask for bits [3:0] in ADI register 15
  [19:16] D1L — Data for bits [3:0] in ADI register 15, only bits selected by mask M1L will be affected by access
  [15:12] M0H — Mask for bits [7:4] in ADI register 14
  [11:8] D0H — Data for bits [7:4] in ADI register 14, only bits selected by mask M0H will be affected by access
  [7:4] M0L — Mask for bits [3:0] in ADI register 14
  [3:0] D0L — Data for bits [3:0] in ADI register 14, only bits selected by mask M0L will be affected by access
0xC60 MASK8B01 wo — Masked Access (8m/8d), Byte Offsets 0 and 1.
  [31:24] M1 — Mask for ADI register 1
  [23:16] D1 — Data for ADI register 1, only bits selected by mask M1 will be affected by access
  [15:8] M0 — Mask for ADI register 0
  [7:0] D0 — Data for ADI register 0, only bits selected by mask M0 will be affected by access
0xC64 MASK8B23 wo — Masked Access (8m/8d), Byte Offsets 2 and 3.
  [31:24] M1 — Mask for ADI register 3
  [23:16] D1 — Data for ADI register 3, only bits selected by mask M1 will be affected by access
  [15:8] M0 — Mask for ADI register 2
  [7:0] D0 — Data for ADI register 2, only bits selected by mask M0 will be affected by access
0xC68 MASK8B45 wo — Masked Access (8m/8d), Byte Offsets 4 and 5.
  [31:24] M1 — Mask for ADI register 5
  [23:16] D1 — Data for ADI register 5, only bits selected by mask M1 will be affected by access
  [15:8] M0 — Mask for ADI register 4
  [7:0] D0 — Data for ADI register 4, only bits selected by mask M0 will be affected by access
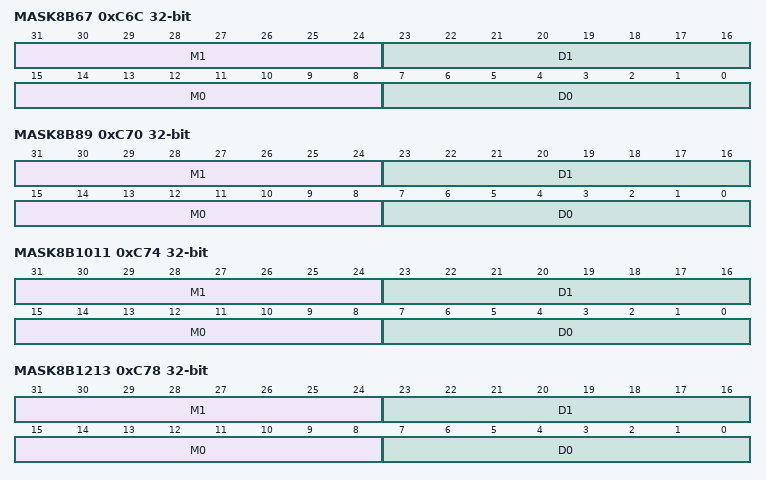
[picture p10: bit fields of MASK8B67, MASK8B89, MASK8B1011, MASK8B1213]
0xC6C MASK8B67 wo — Masked Access (8m/8d), Byte Offsets 6 and 7.
  [31:24] M1 — Mask for ADI register 7
  [23:16] D1 — Data for ADI register 7, only bits selected by mask M1 will be affected by access
  [15:8] M0 — Mask for ADI register 6
  [7:0] D0 — Data for ADI register 6, only bits selected by mask M0 will be affected by access
0xC70 MASK8B89 wo — Masked Access (8m/8d), Byte Offsets 8 and 9.
  [31:24] M1 — Mask for ADI register 9
  [23:16] D1 — Data for ADI register 9, only bits selected by mask M1 will be affected by access
  [15:8] M0 — Mask for ADI register 8
  [7:0] D0 — Data for ADI register 8, only bits selected by mask M0 will be affected by access
0xC74 MASK8B1011 wo — Masked Access (8m/8d), Byte Offsets 10 and 11.
  [31:24] M1 — Mask for ADI register 11
  [23:16] D1 — Data for ADI register 11, only bits selected by mask M1 will be affected by access
  [15:8] M0 — Mask for ADI register 10
  [7:0] D0 — Data for ADI register 10, only bits selected by mask M0 will be affected by access
0xC78 MASK8B1213 wo — Masked Access (8m/8d), Byte Offsets 12 and 13.
  [31:24] M1 — Mask for ADI register 13
  [23:16] D1 — Data for ADI register 13, only bits selected by mask M1 will be affected by access
  [15:8] M0 — Mask for ADI register 12
  [7:0] D0 — Data for ADI register 12, only bits selected by mask M0 will be affected by access
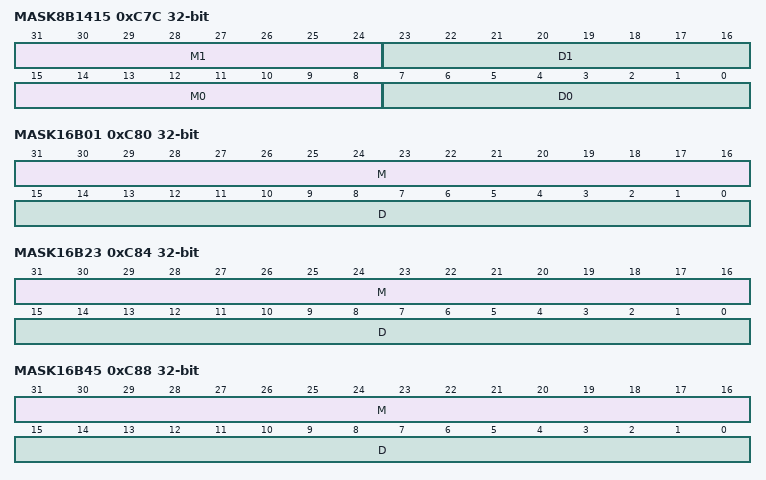
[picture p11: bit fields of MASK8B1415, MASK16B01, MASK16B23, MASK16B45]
0xC7C MASK8B1415 wo — Masked Access (8m/8d), Byte Offsets 14 and 15.
  [31:24] M1 — Mask for ADI register 15
  [23:16] D1 — Data for ADI register 15, only bits selected by mask M1 will be affected by access
  [15:8] M0 — Mask for ADI register 14
  [7:0] D0 — Data for ADI register 14, only bits selected by mask M0 will be affected by access
0xC80 MASK16B01 wo — Masked Access (16m/16d), Byte Offsets 0 and 1.
  [31:16] M — Mask for ADI register 0 and 1
  [15:0] D — Data for ADI register 0 and 1, only bits selected by mask M will be affected by access
0xC84 MASK16B23 wo — Masked Access (16m/16d), Byte Offsets 2 and 3.
  [31:16] M — Mask for ADI register 2 and 3
  [15:0] D — Data for ADI register 2 and 3, only bits selected by mask M will be affected by access
0xC88 MASK16B45 wo — Masked Access (16m/16d), Byte Offsets 4 and 5.
  [31:16] M — Mask for ADI register 4 and 5
  [15:0] D — Data for ADI register 4 and 5, only bits selected by mask M will be affected by access
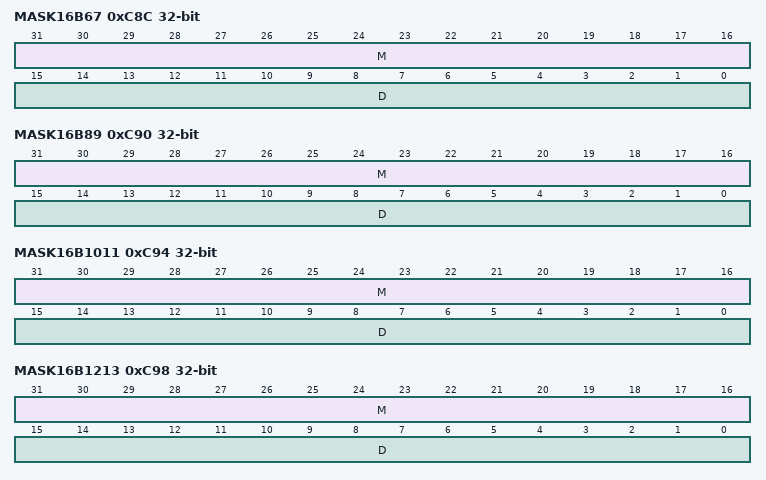
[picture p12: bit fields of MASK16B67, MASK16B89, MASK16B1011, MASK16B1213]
0xC8C MASK16B67 wo — Masked Access (16m/16d), Byte Offsets 6 and 7.
  [31:16] M — Mask for ADI register 6 and 7
  [15:0] D — Data for ADI register 6 and 7, only bits selected by mask M will be affected by access
0xC90 MASK16B89 wo — Masked Access (16m/16d), Byte Offsets 8 and 9.
  [31:16] M — Mask for ADI register 8 and 9
  [15:0] D — Data for ADI register 8 and 9, only bits selected by mask M will be affected by access
0xC94 MASK16B1011 wo — Masked Access (16m/16d), Byte Offsets 10 and 11.
  [31:16] M — Mask for ADI register 10 and 11
  [15:0] D — Data for ADI register 10 and 11, only bits selected by mask M will be affected by access
0xC98 MASK16B1213 wo — Masked Access (16m/16d), Byte Offsets 12 and 13.
  [31:16] M — Mask for ADI register 12 and 13
  [15:0] D — Data for ADI register 12 and 13, only bits selected by mask M will be affected by access
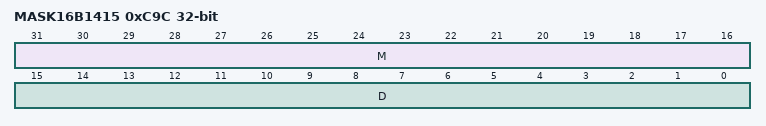
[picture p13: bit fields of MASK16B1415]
0xC9C MASK16B1415 wo — Masked Access (16m/16d), Byte Offsets 14 and 15.
  [31:16] M — Mask for ADI register 14 and 15
  [15:0] D — Data for ADI register 14 and 15, only bits selected by mask M will be affected by access
